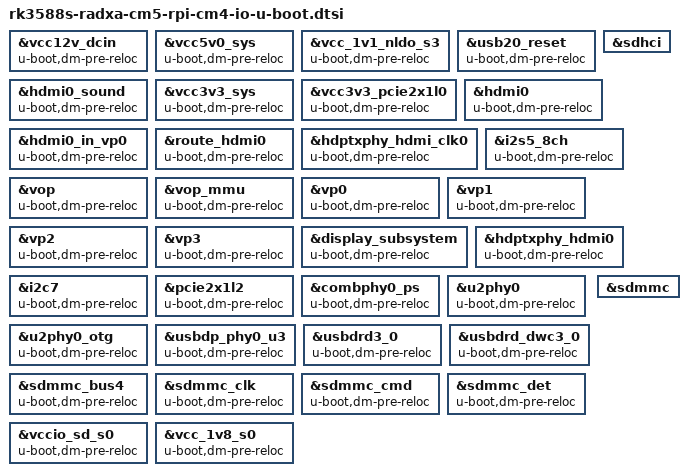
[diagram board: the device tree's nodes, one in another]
// SPDX-License-Identifier: (GPL-2.0+ OR MIT)
/*
 * Copyright (c) 2024 Rockchip Electronics Co., Ltd.
 * Copyright (c) 2024 Radxa Computer (Shenzhen) Co., Ltd.
 *
 */

#include "rk3588s-radxa-cm5-u-boot.dtsi"

&vcc12v_dcin {
	u-boot,dm-pre-reloc;
};

&vcc5v0_sys {
	u-boot,dm-pre-reloc;
};

&vcc_1v1_nldo_s3 {
	u-boot,dm-pre-reloc;
};

&usb20_reset {
	u-boot,dm-pre-reloc;
};

&hdmi0_sound {
	u-boot,dm-pre-reloc;
};

&vcc3v3_sys {
	u-boot,dm-pre-reloc;
};

&vcc3v3_pcie2x1l0 {
	u-boot,dm-pre-reloc;
};

&sdhci {
	u-boot,dm-spl;
};

&hdmi0 {
	u-boot,dm-pre-reloc;
};

&hdmi0_in_vp0 {
	u-boot,dm-pre-reloc;
};

&route_hdmi0 {
	u-boot,dm-pre-reloc;
};

&hdptxphy_hdmi_clk0 {
	u-boot,dm-pre-reloc;
};

&i2s5_8ch {
	u-boot,dm-pre-reloc;
};

&vop {
	u-boot,dm-pre-reloc;
};

&vop_mmu {
	u-boot,dm-pre-reloc;
};

&vp0 {
	u-boot,dm-pre-reloc;
};

&vp1 {
	u-boot,dm-pre-reloc;
};

&vp2 {
	u-boot,dm-pre-reloc;
};

&vp3 {
	u-boot,dm-pre-reloc;
};

&display_subsystem {
	u-boot,dm-pre-reloc;
};

&hdptxphy_hdmi0 {
	u-boot,dm-pre-reloc;
};

&i2c7 {
	u-boot,dm-pre-reloc;
};

&pcie2x1l2 {
	u-boot,dm-pre-reloc;
};

&combphy0_ps {
	u-boot,dm-pre-reloc;
};

&u2phy0 {
	u-boot,dm-pre-reloc;
};

&u2phy0_otg {
	u-boot,dm-pre-reloc;
};

&usbdp_phy0_u3 {
	u-boot,dm-pre-reloc;
};

&usbdrd3_0 {
	u-boot,dm-pre-reloc;
};

&usbdrd_dwc3_0 {
	u-boot,dm-pre-reloc;
};

&sdmmc {
	u-boot,dm-spl;
};

&sdmmc_bus4 {
	u-boot,dm-pre-reloc;
};

&sdmmc_clk {
	u-boot,dm-pre-reloc;
};

&sdmmc_cmd {
	u-boot,dm-pre-reloc;
};

&sdmmc_det {
	u-boot,dm-pre-reloc;
};

&vccio_sd_s0 {
	u-boot,dm-pre-reloc;
};

&vcc_1v8_s0 {
	u-boot,dm-pre-reloc;
};
